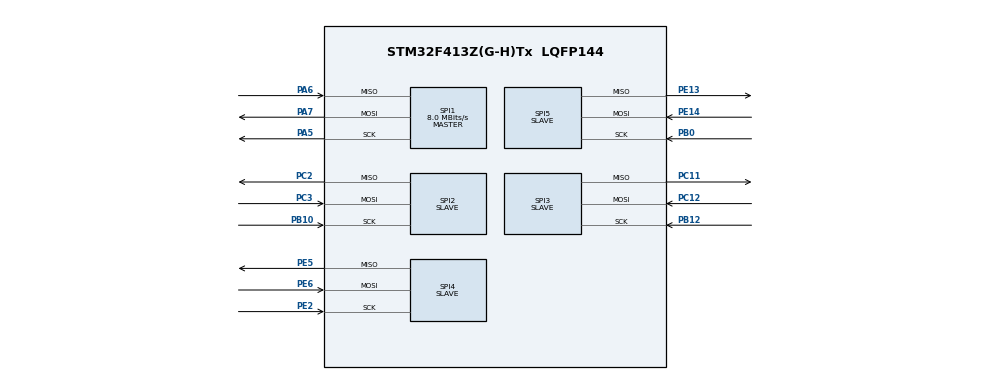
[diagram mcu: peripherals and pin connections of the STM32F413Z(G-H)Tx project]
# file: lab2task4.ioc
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Mcu.Family=STM32F4
Mcu.Name=STM32F413Z(G-H)Tx
Mcu.Package=LQFP144
NVIC.PriorityGroup=NVIC_PRIORITYGROUP_4
PA5.Mode=Full_Duplex_Master
PA5.Signal=SPI1_SCK
PA6.Mode=Full_Duplex_Master
PA6.Signal=SPI1_MISO
PA7.Mode=Full_Duplex_Master
PA7.Signal=SPI1_MOSI
PB0.Mode=Full_Duplex_Slave
PB0.Signal=SPI5_SCK
PB10.Mode=Full_Duplex_Slave
PB10.Signal=SPI2_SCK
PB12.Mode=Full_Duplex_Slave
PB12.Signal=SPI3_SCK
PC11.Mode=Full_Duplex_Slave
PC11.Signal=SPI3_MISO
PC12.Mode=Full_Duplex_Slave
PC12.Signal=SPI3_MOSI
PC2.Mode=Full_Duplex_Slave
PC2.Signal=SPI2_MISO
PC3.Mode=Full_Duplex_Slave
PC3.Signal=SPI2_MOSI
PE13.Mode=Full_Duplex_Slave
PE13.Signal=SPI5_MISO
PE14.Mode=Full_Duplex_Slave
PE14.Signal=SPI5_MOSI
PE2.Mode=Full_Duplex_Slave
PE2.Signal=SPI4_SCK
PE5.Mode=Full_Duplex_Slave
PE5.Signal=SPI4_MISO
PE6.Mode=Full_Duplex_Slave
PE6.Signal=SPI4_MOSI
ProjectManager.HeapSize=0x200
ProjectManager.StackSize=0x400
ProjectManager.TargetToolchain=STM32CubeIDE
RCC.CortexFreq_Value=16000000
RCC.USBFreq_Value=96000000
RCC.VCOOutputFreq_Value=192000000
SPI1.CalculateBaudRate=8.0 MBits/s
SPI1.Direction=SPI_DIRECTION_2LINES
SPI1.Mode=SPI_MODE_MASTER
SPI1.VirtualType=VM_MASTER
SPI2.Direction=SPI_DIRECTION_2LINES
SPI2.Mode=SPI_MODE_SLAVE
SPI2.VirtualType=VM_SLAVE
SPI3.Direction=SPI_DIRECTION_2LINES
SPI3.Mode=SPI_MODE_SLAVE
SPI3.VirtualType=VM_SLAVE
SPI4.Direction=SPI_DIRECTION_2LINES
SPI4.Mode=SPI_MODE_SLAVE
SPI4.VirtualType=VM_SLAVE
SPI5.Direction=SPI_DIRECTION_2LINES
SPI5.Mode=SPI_MODE_SLAVE
SPI5.VirtualType=VM_SLAVE
board=custom

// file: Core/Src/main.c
/* USER CODE BEGIN Header */
/**
  ******************************************************************************
  * @file           : main.c
  * @brief          : Main program body
  ******************************************************************************
  * @attention
  *
  * <h2><center>&copy; Copyright (c) 2020 STMicroelectronics.
  * All rights reserved.</center></h2>
  *
  * This software component is licensed by ST under BSD 3-Clause license,
  * the "License"; You may not use this file except in compliance with the
  * License. You may obtain a copy of the License at:
  *                        opensource.org/licenses/BSD-3-Clause
  *
  ******************************************************************************
  */
/* USER CODE END Header */

#include "main.h"
#include "stm32f4xx_hal_conf.h"
#define ESC 27

SPI_HandleTypeDef hspi1; // connected to master terminal
SPI_HandleTypeDef hspi2; // connected to V_MAG register for firmware version
SPI_HandleTypeDef hspi3; // connected to CTL_Reg
SPI_HandleTypeDef hspi4; // connected to TMP_LO
SPI_HandleTypeDef hspi5; // connected to STS_REG

void SystemClock_Config(void);
static void MX_GPIO_Init(void);
static void MX_SPI1_Init(void);
static void MX_SPI2_Init(void);
static void MX_SPI3_Init(void);
static void MX_SPI4_Init(void);
static void MX_SPI5_Init(void);

int main(void)
{

  /* MCU Configuration--------------------------------------------------------*/

  /* Reset of all peripherals, Initializes the Flash interface and the Systick. */
  HAL_Init();

  /* Configure the system clock */
  SystemClock_Config();

  /* Initialize all configured peripherals */
  MX_GPIO_Init();
  MX_SPI1_Init();
  MX_SPI2_Init();
  MX_SPI3_Init();
  MX_SPI4_Init();
  MX_SPI5_Init();
  /* USER CODE BEGIN 2 */

  char readbuffer[10];

  HAL_SPI_Receive(&hspi2, readbuffer[10], 10, 100);
  HAL_SPI_Transmit(&hspi1, readbuffer[10], 10, 100);

  /* USER CODE END 2 */

  /* Infinite loop */
  while (1)
  {

	  char commandline[107] = "1 - read firmware; 2- Trigger temp measurement; 3- change device id; 4- clear and reset slave terminal";
	  HAL_SPI_Receive(&hspi1, readbuffer, 10, 100);
	  if(readbuffer[0] == ESC)
	  {
		  HAL_SPI_Transmit(&hspi1, commandline, 104, 100 );
		  _Bool inputhasrecieved = 0;
		  while(!inputhasrecieved)
		  {
			  HAL_SPI_Receive(&hspi1, readbuffer, 10, 100);
			  if(readbuffer[0] == '1') // read firmware
			  {
				  HAL_SPI_Receive(&hspi2, readbuffer, 10, 100);
				  HAL_SPI_Transmit(&hspi1, readbuffer, 10, 100);
				  inputhasrecieved = 1;
			  }
			  else if (readbuffer[0] == '2') //trigger temp measurement
			  {
				  HAL_SPI_Transmit(&hspi3, 1, 10, 100);
				  HAL_SPI_Receive(&hspi5, readbuffer[0], 1, 1);
				  while(readbuffer[0] != 3)
				  {
					  HAL_SPI_Receive(&hspi5, readbuffer[0], 1, 1);
				  }
				  int tmp_lo = 0;
				  HAL_SPI_Receive(&hspi4, tmp_lo, 12, 100);
				  int temperature = 0;
				  temperature = 0.322*tmp_lo - 279;
				  HAL_SPI_Transmit(&hspi1, temperature, 12, 100);
				  inputhasrecieved = 1;
			  }
			  else if (readbuffer[0] == '3') //change device id
			  {
				  HAL_SPI_Transmit(&hspi3, 7, 10, 100);
				  inputhasrecieved = 1;
			  }
			  else if (readbuffer[0] == '4') //clear reset slave terminal
			  {
				  HAL_SPI_Transmit(&hspi3, 3, 10, 100);
				  inputhasrecieved = 1;
			  }
		  }
	  }
  }
}

void SystemClock_Config(void)
{
  RCC_OscInitTypeDef RCC_OscInitStruct = {0};
  RCC_ClkInitTypeDef RCC_ClkInitStruct = {0};

  /** Configure the main internal regulator output voltage
  */
  __HAL_RCC_PWR_CLK_ENABLE();
  __HAL_PWR_VOLTAGESCALING_CONFIG(PWR_REGULATOR_VOLTAGE_SCALE1);
  /** Initializes the CPU, AHB and APB busses clocks
  */
  RCC_OscInitStruct.OscillatorType = RCC_OSCILLATORTYPE_HSI;
  RCC_OscInitStruct.HSIState = RCC_HSI_ON;
  RCC_OscInitStruct.HSICalibrationValue = RCC_HSICALIBRATION_DEFAULT;
  RCC_OscInitStruct.PLL.PLLState = RCC_PLL_NONE;
  if (HAL_RCC_OscConfig(&RCC_OscInitStruct) != HAL_OK)
  {
    Error_Handler();
  }
  /** Initializes the CPU, AHB and APB busses clocks
  */
  RCC_ClkInitStruct.ClockType = RCC_CLOCKTYPE_HCLK|RCC_CLOCKTYPE_SYSCLK
                              |RCC_CLOCKTYPE_PCLK1|RCC_CLOCKTYPE_PCLK2;
  RCC_ClkInitStruct.SYSCLKSource = RCC_SYSCLKSOURCE_HSI;
  RCC_ClkInitStruct.AHBCLKDivider = RCC_SYSCLK_DIV1;
  RCC_ClkInitStruct.APB1CLKDivider = RCC_HCLK_DIV1;
  RCC_ClkInitStruct.APB2CLKDivider = RCC_HCLK_DIV1;

  if (HAL_RCC_ClockConfig(&RCC_ClkInitStruct, FLASH_LATENCY_0) != HAL_OK)
  {
    Error_Handler();
  }
}

static void MX_SPI1_Init(void)
{

  /* SPI1 parameter configuration*/
  hspi1.Instance = SPI1;
  hspi1.Init.Mode = SPI_MODE_MASTER;
  hspi1.Init.Direction = SPI_DIRECTION_2LINES;
  hspi1.Init.DataSize = SPI_DATASIZE_8BIT;
  hspi1.Init.CLKPolarity = SPI_POLARITY_LOW;
  hspi1.Init.CLKPhase = SPI_PHASE_1EDGE;
  hspi1.Init.NSS = SPI_NSS_SOFT;
  hspi1.Init.BaudRatePrescaler = SPI_BAUDRATEPRESCALER_2;
  hspi1.Init.FirstBit = SPI_FIRSTBIT_MSB;
  hspi1.Init.TIMode = SPI_TIMODE_DISABLE;
  hspi1.Init.CRCCalculation = SPI_CRCCALCULATION_DISABLE;
  hspi1.Init.CRCPolynomial = 10;
  if (HAL_SPI_Init(&hspi1) != HAL_OK)
  {
    Error_Handler();
  }

}

static void MX_SPI2_Init(void)
{

  /* SPI2 parameter configuration*/
  hspi2.Instance = SPI2;
  hspi2.Init.Mode = SPI_MODE_SLAVE;
  hspi2.Init.Direction = SPI_DIRECTION_2LINES;
  hspi2.Init.DataSize = SPI_DATASIZE_8BIT;
  hspi2.Init.CLKPolarity = SPI_POLARITY_LOW;
  hspi2.Init.CLKPhase = SPI_PHASE_1EDGE;
  hspi2.Init.NSS = SPI_NSS_SOFT;
  hspi2.Init.FirstBit = SPI_FIRSTBIT_MSB;
  hspi2.Init.TIMode = SPI_TIMODE_DISABLE;
  hspi2.Init.CRCCalculation = SPI_CRCCALCULATION_DISABLE;
  hspi2.Init.CRCPolynomial = 10;
  if (HAL_SPI_Init(&hspi2) != HAL_OK)
  {
    Error_Handler();
  }

}

static void MX_SPI3_Init(void)
{

  /* SPI3 parameter configuration*/
  hspi3.Instance = SPI3;
  hspi3.Init.Mode = SPI_MODE_SLAVE;
  hspi3.Init.Direction = SPI_DIRECTION_2LINES;
  hspi3.Init.DataSize = SPI_DATASIZE_8BIT;
  hspi3.Init.CLKPolarity = SPI_POLARITY_LOW;
  hspi3.Init.CLKPhase = SPI_PHASE_1EDGE;
  hspi3.Init.NSS = SPI_NSS_SOFT;
  hspi3.Init.FirstBit = SPI_FIRSTBIT_MSB;
  hspi3.Init.TIMode = SPI_TIMODE_DISABLE;
  hspi3.Init.CRCCalculation = SPI_CRCCALCULATION_DISABLE;
  hspi3.Init.CRCPolynomial = 10;
  if (HAL_SPI_Init(&hspi3) != HAL_OK)
  {
    Error_Handler();
  }

}

static void MX_SPI4_Init(void)
{

  /* SPI4 parameter configuration*/
  hspi4.Instance = SPI4;
  hspi4.Init.Mode = SPI_MODE_SLAVE;
  hspi4.Init.Direction = SPI_DIRECTION_2LINES;
  hspi4.Init.DataSize = SPI_DATASIZE_8BIT;
  hspi4.Init.CLKPolarity = SPI_POLARITY_LOW;
  hspi4.Init.CLKPhase = SPI_PHASE_1EDGE;
  hspi4.Init.NSS = SPI_NSS_SOFT;
  hspi4.Init.FirstBit = SPI_FIRSTBIT_MSB;
  hspi4.Init.TIMode = SPI_TIMODE_DISABLE;
  hspi4.Init.CRCCalculation = SPI_CRCCALCULATION_DISABLE;
  hspi4.Init.CRCPolynomial = 10;
  if (HAL_SPI_Init(&hspi4) != HAL_OK)
  {
    Error_Handler();
  }

}

static void MX_SPI5_Init(void)
{

  /* SPI5 parameter configuration*/
  hspi5.Instance = SPI5;
  hspi5.Init.Mode = SPI_MODE_SLAVE;
  hspi5.Init.Direction = SPI_DIRECTION_2LINES;
  hspi5.Init.DataSize = SPI_DATASIZE_8BIT;
  hspi5.Init.CLKPolarity = SPI_POLARITY_LOW;
  hspi5.Init.CLKPhase = SPI_PHASE_1EDGE;
  hspi5.Init.NSS = SPI_NSS_SOFT;
  hspi5.Init.FirstBit = SPI_FIRSTBIT_MSB;
  hspi5.Init.TIMode = SPI_TIMODE_DISABLE;
  hspi5.Init.CRCCalculation = SPI_CRCCALCULATION_DISABLE;
  hspi5.Init.CRCPolynomial = 10;
  if (HAL_SPI_Init(&hspi5) != HAL_OK)
  {
    Error_Handler();
  }

}

static void MX_GPIO_Init(void)
{

  /* GPIO Ports Clock Enable */
  __HAL_RCC_GPIOE_CLK_ENABLE();
  __HAL_RCC_GPIOC_CLK_ENABLE();
  __HAL_RCC_GPIOA_CLK_ENABLE();
  __HAL_RCC_GPIOB_CLK_ENABLE();

}

void Error_Handler(void)
{
}

/************************ (C) COPYRIGHT STMicroelectronics *****END OF FILE****/
